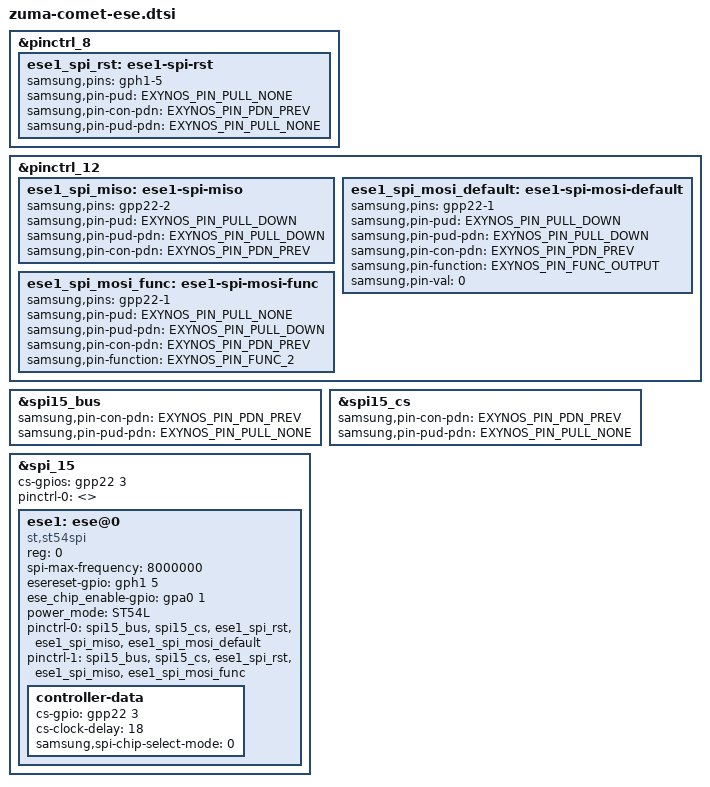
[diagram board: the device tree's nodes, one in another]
// SPDX-License-Identifier: GPL-2.0-only
/*
 * eSE device tree source for comet
 *
 * Copyright 2023 Google LLC.
 *
 */

#include <arm64/exynos/exynos-pinctrl.h>

&pinctrl_8 {
        ese1_spi_rst: ese1-spi-rst {
                samsung,pins ="gph1-5";
                samsung,pin-pud = <EXYNOS_PIN_PULL_NONE>;
                samsung,pin-con-pdn = <EXYNOS_PIN_PDN_PREV>;
                samsung,pin-pud-pdn = <EXYNOS_PIN_PULL_NONE>;
        };
};

&pinctrl_12 {
        ese1_spi_miso: ese1-spi-miso {
                samsung,pins ="gpp22-2";
                samsung,pin-pud = <EXYNOS_PIN_PULL_DOWN>;
                samsung,pin-pud-pdn = <EXYNOS_PIN_PULL_DOWN>;
                samsung,pin-con-pdn = <EXYNOS_PIN_PDN_PREV>;
        };
        ese1_spi_mosi_default: ese1-spi-mosi-default {
                samsung,pins ="gpp22-1";
                samsung,pin-pud = <EXYNOS_PIN_PULL_DOWN>;
                samsung,pin-pud-pdn = <EXYNOS_PIN_PULL_DOWN>;
                samsung,pin-con-pdn = <EXYNOS_PIN_PDN_PREV>;
                samsung,pin-function = <EXYNOS_PIN_FUNC_OUTPUT>;
                samsung,pin-val = <0>;
        };
        ese1_spi_mosi_func: ese1-spi-mosi-func {
                samsung,pins ="gpp22-1";
                samsung,pin-pud = <EXYNOS_PIN_PULL_NONE>;
                samsung,pin-pud-pdn = <EXYNOS_PIN_PULL_DOWN>;
                samsung,pin-con-pdn = <EXYNOS_PIN_PDN_PREV>;
                samsung,pin-function = <EXYNOS_PIN_FUNC_2>;
        };
};

&spi15_bus {
        samsung,pin-con-pdn = <EXYNOS_PIN_PDN_PREV>;
        samsung,pin-pud-pdn = <EXYNOS_PIN_PULL_NONE>;
};

&spi15_cs {
        samsung,pin-con-pdn = <EXYNOS_PIN_PDN_PREV>;
        samsung,pin-pud-pdn = <EXYNOS_PIN_PULL_NONE>;
};


&spi_15 {
        #address-cells = <1>;
        #size-cells = <0>;
        status = "okay";
        cs-gpios = <&gpp22 3 GPIO_ACTIVE_HIGH>;
        pinctrl-0 = <>;

        ese1: ese@0 {
                compatible = "st,st54spi";
                reg = <0>;
                spi-max-frequency = <8000000>;
                esereset-gpio = <&gph1 5 GPIO_ACTIVE_HIGH>;
#ifndef ESIM_NO_CHIP_ENABLE_PIN
                ese_chip_enable-gpio = <&gpa0 1 GPIO_ACTIVE_HIGH>;
#endif
                power_mode = "ST54L";
                pinctrl-names = "default","func";
                pinctrl-0 = <&spi15_bus &spi15_cs &ese1_spi_rst &ese1_spi_miso &ese1_spi_mosi_default>;
                pinctrl-1 = <&spi15_bus &spi15_cs &ese1_spi_rst &ese1_spi_miso &ese1_spi_mosi_func>;
                controller-data {
                        cs-gpio = <&gpp22 3 GPIO_ACTIVE_HIGH>;
                        cs-clock-delay = <18>;
                        samsung,spi-chip-select-mode = <0>;
                };
        };
};

